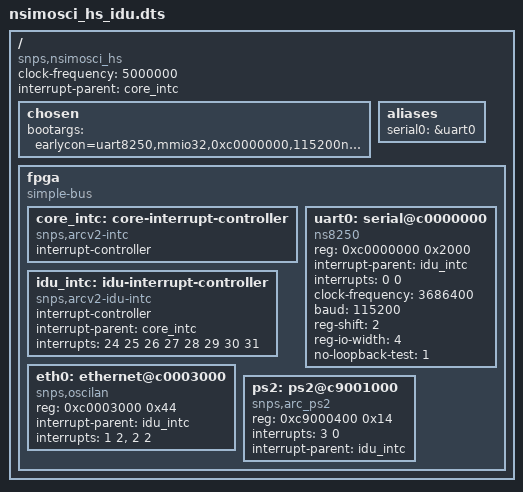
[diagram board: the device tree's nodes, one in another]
/*
 * Copyright (C) 2013 Synopsys, Inc. (www.synopsys.com)
 *
 * This program is free software; you can redistribute it and/or modify
 * it under the terms of the GNU General Public License version 2 as
 * published by the Free Software Foundation.
 */
/dts-v1/;

/include/ "skeleton.dtsi"

/ {
	compatible = "snps,nsimosci_hs";
	clock-frequency = <5000000>;	/* 5 MHZ */
	#address-cells = <1>;
	#size-cells = <1>;
	interrupt-parent = <&core_intc>;

	chosen {
		/* this is for console on serial */
		bootargs = "earlycon=uart8250,mmio32,0xc0000000,115200n8 console=ttyS0,115200n8 loglevel=10";
	};

	aliases {
		serial0 = &uart0;
	};

	fpga {
		compatible = "simple-bus";
		#address-cells = <1>;
		#size-cells = <1>;

		/* child and parent address space 1:1 mapped */
		ranges;

		core_intc: core-interrupt-controller {
			compatible = "snps,arcv2-intc";
			interrupt-controller;
			#interrupt-cells = <1>;
/*			interrupts = <16 17 18 19 20 21 22 23 24 25>; */
		};

		idu_intc: idu-interrupt-controller {
			compatible = "snps,arcv2-idu-intc";
			interrupt-controller;
			interrupt-parent = <&core_intc>;
			/* <hwirq  distribution>
			  distribution: 0=RR, n=cpu[n] */
			#interrupt-cells = <2>;
			interrupts = <24 25 26 27 28 29 30 31>;
		};

		uart0: serial@c0000000 {
			compatible = "ns8250";
			reg = <0xc0000000 0x2000>;
			interrupt-parent = <&idu_intc>;
			interrupts = <0 0>;
			clock-frequency = <3686400>;
			baud = <115200>;
			reg-shift = <2>;
			reg-io-width = <4>;
			no-loopback-test = <1>;
		};

		eth0: ethernet@c0003000 {
			compatible = "snps,oscilan";
			reg = <0xc0003000 0x44>;
			interrupt-parent = <&idu_intc>;
			interrupts = <1 2>, <2 2>;
			interrupt-names = "rx", "tx";
		};

		ps2: ps2@c9001000 {
			compatible = "snps,arc_ps2";
			reg = <0xc9000400 0x14>;
			interrupts = <3 0>;
                        interrupt-parent = <&idu_intc>;
			interrupt-names = "arc_ps2_irq";
		};
	};
};
